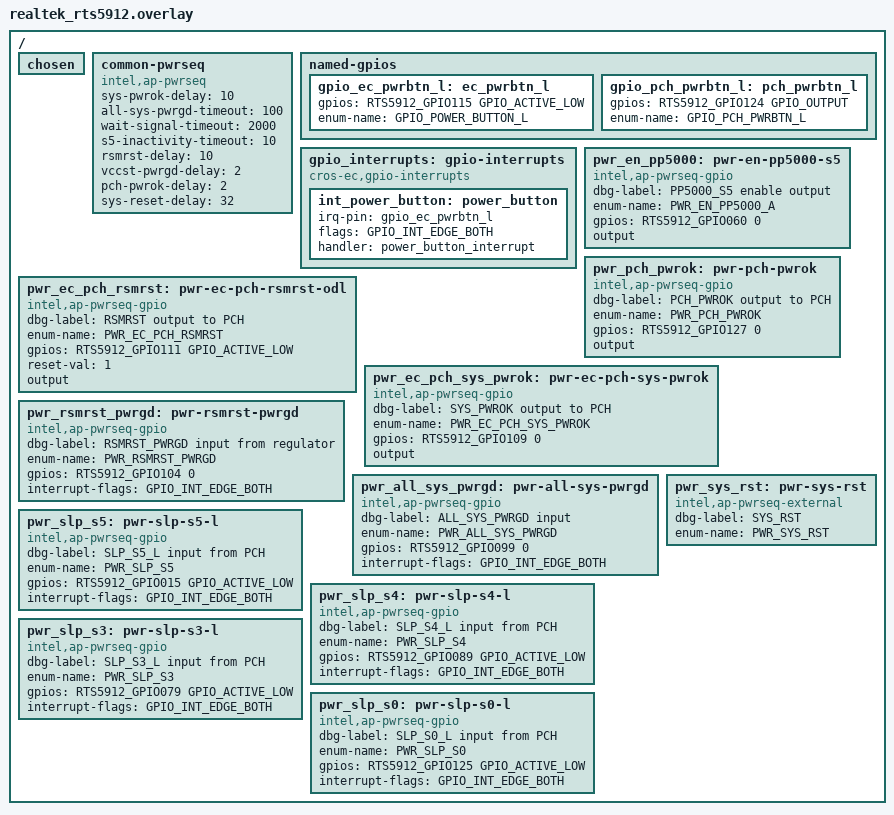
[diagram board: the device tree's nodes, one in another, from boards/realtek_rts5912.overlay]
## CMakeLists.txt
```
# Copyright 2026 The ChromiumOS Authors
# Use of this source code is governed by a BSD-style license that can be
# found in the LICENSE file.

cmake_minimum_required(VERSION 3.20.0)
find_package(Zephyr REQUIRED HINTS $ENV{ZEPHYR_BASE})
project(aic_pwrseq_tests)

target_sources(app PRIVATE src/board_power.c)
```

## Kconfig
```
# Copyright 2026 The ChromiumOS Authors
# Use of this source code is governed by a BSD-style license that can be
# found in the LICENSE file.

config AIC_PWRSEQ_FAULT_INJECTION
	bool "Inject AP power sequencing timing violations for negative testing"
	help
	  Enable deliberate timing violations in the AIC power sequencing test
	  firmware to verify that the Dagwood AP emulator and pytest harness
	  detect spec violations (tPCH12, tPCH03, tPLT04, tPCH08, tPLT05,
	  tPCH43, and tCPU22).

source "Kconfig.zephyr"
```

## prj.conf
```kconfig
# Copyright 2026 The ChromiumOS Authors
# Use of this source code is governed by a BSD-style license that can be
# found in the LICENSE file.

CONFIG_PLATFORM_EC=y
CONFIG_CROS_EC=y
CONFIG_CROS_EC_RO=y
CONFIG_SYSCON=y
CONFIG_SHELL=y
CONFIG_SHELL_BACKEND_SERIAL=y

# Power sequencing with driver
CONFIG_AP=y
CONFIG_AP_PWRSEQ=y
CONFIG_AP_PWRSEQ_DRIVER=y
CONFIG_AP_X86_INTEL_MTL=y
CONFIG_X86_NON_DSX_PWRSEQ_MTL=y
CONFIG_X86_NON_DSX_PWRSEQ_CONSOLE=y
CONFIG_AP_PWRSEQ_S0IX=n
CONFIG_AP_PWRSEQ_STACK_SIZE=2048

# Pure GPIO, disable eSPI virtual wires
CONFIG_PLATFORM_EC_HOST_INTERFACE_ESPI_VW_SLP_S3=n
CONFIG_PLATFORM_EC_HOST_INTERFACE_ESPI_VW_SLP_S4=n
CONFIG_PLATFORM_EC_HOST_INTERFACE_ESPI_VW_SLP_S5=n

# Power button support
CONFIG_PLATFORM_EC_POWER_BUTTON=y
CONFIG_PLATFORM_EC_POWER_BUTTON_X86=y
CONFIG_PLATFORM_EC_EXTPOWER=n
CONFIG_PLATFORM_EC_EXTPOWER_GPIO=n

# Unlocked system for testing
CONFIG_PLATFORM_EC_SYSTEM_UNLOCKED=y

# Disable features not needed for this test
CONFIG_PLATFORM_EC_VBOOT_EFS2=n
CONFIG_PLATFORM_EC_SWITCH=n
CONFIG_PLATFORM_EC_I2C=n
CONFIG_NAMED_ADC_CHANNELS=n
CONFIG_PLATFORM_EC_BACKLIGHT_LID=n
CONFIG_PLATFORM_EC_KEYBOARD=n
CONFIG_PLATFORM_EC_SHA256_HW_ACCELERATE=n
CONFIG_PLATFORM_EC_VBOOT_HASH=n
CONFIG_EC_HOST_CMD=n
CONFIG_PLATFORM_EC_FAN=n
CONFIG_PLATFORM_EC_HIBERNATE=n
```

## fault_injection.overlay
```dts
/* Copyright 2026 The ChromiumOS Authors
 * Use of this source code is governed by a BSD-style license that can be
 * found in the LICENSE file.
 */

/ {
	common-pwrseq {
		/* Violate tPCH03 (< 10 ms): deassert RSMRST# after only 1 ms */
		rsmrst-delay = <1>;
		/* Violate tPLT04 (< 1 ms), tPCH08 (< 1 ms), and tPLT05 (< 10 ms) */
		sys-pwrok-delay = <0>;
		pch-pwrok-delay = <0>;
	};
};
```

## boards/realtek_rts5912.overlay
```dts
/* Copyright 2026 The ChromiumOS Authors
 * Use of this source code is governed by a BSD-style license that can be
 * found in the LICENSE file.
 */

#include "../../../../program/ec-aic/rtk-aic/project.overlay"
#include <dt-bindings/gpio_defines.h>
#include <zephyr/dt-bindings/gpio/realtek-gpio.h>

/ {
	chosen {
		/delete-property/ intel-ap-pwrseq,espi;
	};

	common-pwrseq {
		compatible = "intel,ap-pwrseq";
		sys-pwrok-delay = <10>;
		all-sys-pwrgd-timeout = <100>;
		wait-signal-timeout = <2000>;
		s5-inactivity-timeout = <10>;
		rsmrst-delay = <10>;
		vccst-pwrgd-delay = <2>;
		pch-pwrok-delay = <2>;
		sys-reset-delay = <32>;
	};

	/* Power button input to EC (from Dagwood PE02) */
	named-gpios {
		gpio_ec_pwrbtn_l: ec_pwrbtn_l {
			gpios = <RTS5912_GPIO115 GPIO_ACTIVE_LOW>;
			enum-name = "GPIO_POWER_BUTTON_L";
		};
		gpio_pch_pwrbtn_l: pch_pwrbtn_l {
			gpios = <RTS5912_GPIO124 GPIO_OUTPUT>;
			enum-name = "GPIO_PCH_PWRBTN_L";
		};
	};

	gpio_interrupts: gpio-interrupts {
		compatible = "cros-ec,gpio-interrupts";

		int_power_button: power_button {
			irq-pin = <&gpio_ec_pwrbtn_l>;
			flags = <GPIO_INT_EDGE_BOTH>;
			handler = "power_button_interrupt";
		};
	};

	/* EC Outputs */
	pwr_en_pp5000: pwr-en-pp5000-s5 {
		compatible = "intel,ap-pwrseq-gpio";
		dbg-label = "PP5000_S5 enable output";
		enum-name = "PWR_EN_PP5000_A";
		gpios = <RTS5912_GPIO060 0>;
		output;
	};

	pwr_ec_pch_rsmrst: pwr-ec-pch-rsmrst-odl {
		compatible = "intel,ap-pwrseq-gpio";
		dbg-label = "RSMRST output to PCH";
		enum-name = "PWR_EC_PCH_RSMRST";
		gpios = <RTS5912_GPIO111 GPIO_ACTIVE_LOW>;
		reset-val = <1>;
		output;
	};

	pwr_pch_pwrok: pwr-pch-pwrok {
		compatible = "intel,ap-pwrseq-gpio";
		dbg-label = "PCH_PWROK output to PCH";
		enum-name = "PWR_PCH_PWROK";
		gpios = <RTS5912_GPIO127 0>;
		output;
	};

	pwr_ec_pch_sys_pwrok: pwr-ec-pch-sys-pwrok {
		compatible = "intel,ap-pwrseq-gpio";
		dbg-label = "SYS_PWROK output to PCH";
		enum-name = "PWR_EC_PCH_SYS_PWROK";
		gpios = <RTS5912_GPIO109 0>;
		output;
	};

	/* EC Inputs from AP (Dagwood) */
	pwr_rsmrst_pwrgd: pwr-rsmrst-pwrgd {
		compatible = "intel,ap-pwrseq-gpio";
		dbg-label = "RSMRST_PWRGD input from regulator";
		enum-name = "PWR_RSMRST_PWRGD";
		gpios = <RTS5912_GPIO104 0>;
		interrupt-flags = <GPIO_INT_EDGE_BOTH>;
	};

	pwr_all_sys_pwrgd: pwr-all-sys-pwrgd {
		compatible = "intel,ap-pwrseq-gpio";
		dbg-label = "ALL_SYS_PWRGD input";
		enum-name = "PWR_ALL_SYS_PWRGD";
		gpios = <RTS5912_GPIO099 0>;
		interrupt-flags = <GPIO_INT_EDGE_BOTH>;
	};

	pwr_slp_s5: pwr-slp-s5-l {
		compatible = "intel,ap-pwrseq-gpio";
		dbg-label = "SLP_S5_L input from PCH";
		enum-name = "PWR_SLP_S5";
		gpios = <RTS5912_GPIO015 GPIO_ACTIVE_LOW>;
		interrupt-flags = <GPIO_INT_EDGE_BOTH>;
	};

	pwr_slp_s4: pwr-slp-s4-l {
		compatible = "intel,ap-pwrseq-gpio";
		dbg-label = "SLP_S4_L input from PCH";
		enum-name = "PWR_SLP_S4";
		gpios = <RTS5912_GPIO089 GPIO_ACTIVE_LOW>;
		interrupt-flags = <GPIO_INT_EDGE_BOTH>;
	};

	pwr_slp_s3: pwr-slp-s3-l {
		compatible = "intel,ap-pwrseq-gpio";
		dbg-label = "SLP_S3_L input from PCH";
		enum-name = "PWR_SLP_S3";
		gpios = <RTS5912_GPIO079 GPIO_ACTIVE_LOW>;
		interrupt-flags = <GPIO_INT_EDGE_BOTH>;
	};

	pwr_slp_s0: pwr-slp-s0-l {
		compatible = "intel,ap-pwrseq-gpio";
		dbg-label = "SLP_S0_L input from PCH";
		enum-name = "PWR_SLP_S0";
		gpios = <RTS5912_GPIO125 GPIO_ACTIVE_LOW>;
		interrupt-flags = <GPIO_INT_EDGE_BOTH>;
	};

	/* External signals for MTL state machine */
	pwr_sys_rst: pwr-sys-rst {
		compatible = "intel,ap-pwrseq-external";
		dbg-label = "SYS_RST";
		enum-name = "PWR_SYS_RST";
	};
};
```

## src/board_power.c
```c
/* Copyright 2026 The ChromiumOS Authors
 * Use of this source code is governed by a BSD-style license that can be
 * found in the LICENSE file.
 */

#include "ap_power/ap_pwrseq_sm.h"

#include <zephyr/kernel.h>
#include <zephyr/logging/log.h>

#include <ap_power/ap_power_interface.h>
#include <power_signals.h>
#include <x86_power_signals.h>

#ifdef CONFIG_AIC_PWRSEQ_FAULT_INJECTION
#include "gpio.h"
#include "hooks.h"
#include "power_button.h"

#include <ap_power/ap_pwrseq.h>
#endif

LOG_MODULE_REGISTER(aic_pwrseq_board, LOG_LEVEL_INF);

static void board_ap_power_shutdown(void)
{
	int timeout_ms = 100;

	power_signal_set(PWR_PCH_PWROK, 0);
	power_signal_set(PWR_EC_PCH_SYS_PWROK, 0);
#ifdef CONFIG_AIC_PWRSEQ_FAULT_INJECTION
	/*
	 * Deliberately violate tPCH12 (min 400 ns from RSMRST# assertion to
	 * primary rail drop) by dropping PP5000_A 50 us before asserting
	 * RSMRST#.
	 */
	power_signal_set(PWR_EN_PP5000_A, 0);
	k_busy_wait(50);
	power_signal_set(PWR_EC_PCH_RSMRST, 1);
#else
	power_signal_set(PWR_EC_PCH_RSMRST, 1);
	power_signal_set(PWR_EN_PP5000_A, 0);
#endif

	while (power_signal_get(PWR_RSMRST_PWRGD) && (timeout_ms > 0)) {
		k_msleep(1);
		timeout_ms--;
	}
}

static int board_ap_power_action_g3_entry(void *data)
{
	board_ap_power_shutdown();
	return 0;
}

static int board_ap_power_action_g3_run(void *data)
{
	if (ap_pwrseq_sm_is_event_set(data, AP_PWRSEQ_EVENT_POWER_SHUTDOWN)) {
		board_ap_power_shutdown();
		return 1;
	}

	if (ap_pwrseq_sm_is_event_set(data, AP_PWRSEQ_EVENT_POWER_STARTUP)) {
		power_signal_set(PWR_EN_PP5000_A, 1);
	}

	if (!power_signal_get(PWR_EN_PP5000_A)) {
		return 1;
	}

	return 0;
}

AP_POWER_APP_STATE_DEFINE(G3, board_ap_power_action_g3_entry,
			  board_ap_power_action_g3_run, NULL);

#ifdef CONFIG_AIC_PWRSEQ_FAULT_INJECTION
static int board_ap_power_action_s0_exit(void *data)
{
	if (ap_pwrseq_sm_get_entry_state(data) == AP_POWER_STATE_S3) {
		/*
		 * Violate tCPU22 (> 50 ms max delay from SLP_S3# assert to
		 * PLT_PWROK deassert) by holding in S0 exit for 60 ms.
		 */
		k_msleep(60);
	}
	return 0;
}

AP_POWER_APP_STATE_DEFINE(S0, NULL, NULL, board_ap_power_action_s0_exit);

static void fault_pwrbtn_release(void)
{
	gpio_set_level(GPIO_PCH_PWRBTN_L, 1);
}
DECLARE_DEFERRED(fault_pwrbtn_release);

static void fault_pwrbtn_change(void)
{
	if (power_button_is_pressed() &&
	    ap_pwrseq_get_current_state(ap_pwrseq_get_instance()) ==
		    AP_POWER_STATE_S0) {
		/*
		 * Truncate S0 PWRBTN pulse to 5 ms to violate tPCH43 (min 18
		 * ms).
		 */
		hook_call_deferred(&fault_pwrbtn_release_data,
				   5 * USEC_PER_MSEC);
	}
}
DECLARE_HOOK(HOOK_POWER_BUTTON_CHANGE, fault_pwrbtn_change, HOOK_PRIO_LAST);
#endif

int power_signal_external_init(void)
{
	return 0;
}

int board_power_signal_get(enum power_signal signal)
{
	switch (signal) {
	case PWR_SYS_RST:
		return 0;
	default:
		LOG_WRN("Unknown board signal get: %d", signal);
		return 1;
	}
}

int board_power_signal_set(enum power_signal signal, int value)
{
	return 0;
}

void ap_power_set_active_wake_mask(void)
{
}
```
